# VSIM32 register map
Vendor: Vesper; File version: 1.0
Simulated 32-bit microcontroller for Silicon register-model tests
Registers are 32-bit, read-write, reset 0x0 unless marked. A register's access mark holds for its fields unless they carry their own. Offsets are from the block's base; lines under a group give offsets from that group; [hi:lo] are bit positions; {n}, {i} and the like mark numbered series; 'fields as' and 'values as' point back to an identical list; <NAME> marks a mode.

## Memory map
0x40003800 SPI2 size 0x400
0x40004000 UART0 size 0x100
0x40013000 SPI1 size 0x400 — Serial peripheral interface
0x40028000 ETHMAC size 0x100 — Ethernet MAC interrupt block

## Interrupts
35 SPI1
42 ETH (ETHMAC)

## SPI1 — Serial peripheral interface
Base 0x40013000
Same registers: SPI2 0x40003800
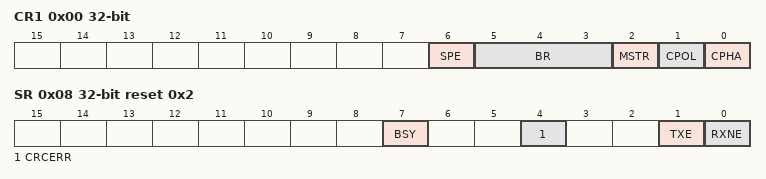
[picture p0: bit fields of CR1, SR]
0x00 CR1 — Control register 1
  [6] SPE, [5:3] BR, [2] MSTR, [1] CPOL, [0] CPHA
0x08 SR reset 0x2 — Status register
  [7] BSY ro, [4] CRCERR write-1-clears, [1] TXE ro, [0] RXNE ro
0x0C DR 16-bit — Data register

## ETHMAC — Ethernet MAC interrupt block
Base 0x40028000
0x00 MAC_ID ro reset 0x56455350
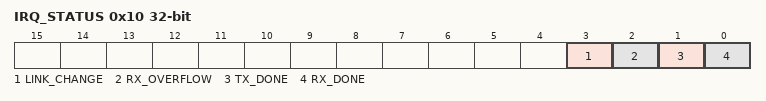
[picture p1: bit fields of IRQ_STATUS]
0x10 IRQ_STATUS write-1-clears — Pending interrupts, write 1 to acknowledge
  [3] LINK_CHANGE, [2] RX_OVERFLOW, [1] TX_DONE, [0] RX_DONE
0x14 IRQ_ENABLE
  [3:0] MASK

## UART0
Base 0x40004000
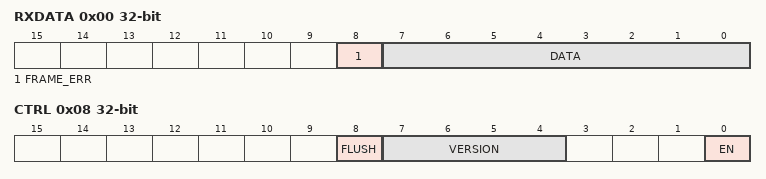
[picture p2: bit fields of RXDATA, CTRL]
0x00 RXDATA ro read-clears — Received byte; reading pops it and clears the flags
  [8] FRAME_ERR, [7:0] DATA
0x04 TXDATA wo
  [7:0] DATA
0x08 CTRL
  [8] FLUSH write-1-sets, [7:4] VERSION ro, [0] EN

## Notices in the file
It follows the CMSIS-SVD schema (https://open-cmsis-pack.github.io/svd-spec/)
and is loosely modelled on common Cortex-M SPI/UART/Ethernet-MAC register
layouts. It describes no real device. Licence: same as this repository.
